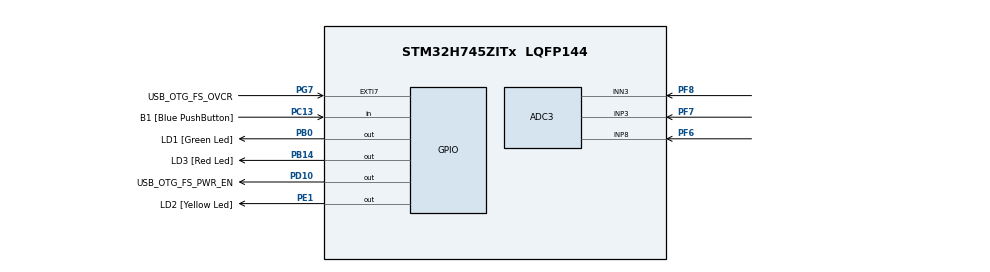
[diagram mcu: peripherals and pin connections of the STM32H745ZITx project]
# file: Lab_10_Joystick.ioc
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ADC3.Channel-0\#ChannelRegularConversion=ADC_CHANNEL_8
ADC3.Channel-1\#ChannelRegularConversion=ADC_CHANNEL_3
ADC3.DiscontinuousConvMode=ENABLE
ADC3.NbrOfConversion=2
ADC3.NbrOfConversionFlag=1
ADC3.OffsetNumber-0\#ChannelRegularConversion=ADC_OFFSET_NONE
ADC3.OffsetNumber-1\#ChannelRegularConversion=ADC_OFFSET_NONE
ADC3.OffsetSignedSaturation-0\#ChannelRegularConversion=DISABLE
ADC3.OffsetSignedSaturation-1\#ChannelRegularConversion=DISABLE
ADC3.Rank-0\#ChannelRegularConversion=1
ADC3.Rank-1\#ChannelRegularConversion=2
ADC3.SamplingTime-0\#ChannelRegularConversion=ADC_SAMPLETIME_1CYCLE_5
ADC3.SamplingTime-1\#ChannelRegularConversion=ADC_SAMPLETIME_1CYCLE_5
ADC3.SingleDiff-1\#ChannelRegularConversion=ADC_DIFFERENTIAL_ENDED
CortexM4.IPs=FATFS_M4\:I,FREERTOS_M4\:I,IWDG2\:I,RCC,WWDG2\:I,DMA,BDMA,MDMA,NVIC2\:I,USART3,ETH,DEBUG,PDM2PCM_M4\:I,PWR,RESMGR_UTILITY,SYS_M4\:I,USB_DEVICE_M4\:I,USB_HOST_M4\:I,CORTEX_M4\:I,GPIO,OPENAMP_M4\:I,VREFBUF
CortexM7.IPs=FATFS_M7\:I,FREERTOS_M7\:I,IWDG1\:I,RCC\:I,WWDG1\:I,DMA\:I,BDMA\:I,MDMA\:I,NVIC1\:I,SYS\:I,USART3\:I,USB_OTG_FS\:I,ETH\:I,CORTEX_M7\:I,DEBUG\:I,PDM2PCM_M7\:I,PWR\:I,RESMGR_UTILITY\:I,USB_DEVICE_M7\:I,USB_HOST_M7\:I,GPIO\:I,OPENAMP_M7\:I,VREFBUF\:I,ADC3\:I
Mcu.Family=STM32H7
Mcu.Name=STM32H745ZITx
Mcu.Package=LQFP144
NVIC1.PriorityGroup=NVIC_PRIORITYGROUP_4
NVIC2.PriorityGroup=NVIC_PRIORITYGROUP_4
PA1.PinAttribute=CortexM7
PA1.Signal=ETH_REF_CLK
PA11.PinAttribute=CortexM7
PA11.Signal=USB_OTG_FS_DM
PA12.PinAttribute=CortexM7
PA12.Signal=USB_OTG_FS_DP
PA2.PinAttribute=CortexM7
PA2.Signal=ETH_MDIO
PA7.PinAttribute=CortexM7
PA7.Signal=ETH_CRS_DV
PA9.PinAttribute=CortexM7
PA9.Signal=USB_OTG_FS_VBUS
PB0.GPIO_Label=LD1 [Green Led]
PB0.PinAttribute=Free
PB0.Signal=GPIO_Output
PB13.PinAttribute=CortexM7
PB13.Signal=ETH_TXD1
PB14.GPIO_Label=LD3 [Red Led]
PB14.PinAttribute=Free
PB14.Signal=GPIO_Output
PC13.GPIO_Label=B1 [Blue PushButton]
PC13.PinAttribute=Free
PC13.Signal=GPIO_Input
PC14-OSC32_IN\ (OSC32_IN).PinAttribute=CortexM7
PC14-OSC32_IN\ (OSC32_IN).Signal=RCC_OSC32_IN
PC15-OSC32_OUT\ (OSC32_OUT).PinAttribute=CortexM7
PC15-OSC32_OUT\ (OSC32_OUT).Signal=RCC_OSC32_OUT
PC4.PinAttribute=CortexM7
PC4.Signal=ETH_RXD0
PC5.PinAttribute=CortexM7
PC5.Signal=ETH_RXD1
PD10.GPIO_Label=USB_OTG_FS_PWR_EN
PD10.PinAttribute=Free
PD10.Signal=GPIO_Output
PD8.GPIO_Label=STLINK_RX
PD8.PinAttribute=CortexM7
PD8.Signal=USART3_TX
PD9.GPIO_Label=STLINK_TX
PD9.PinAttribute=CortexM7
PD9.Signal=USART3_RX
PE1.GPIO_Label=LD2 [Yellow Led]
PE1.PinAttribute=Free
PE1.Signal=GPIO_Output
PF6.Mode=IN8-Single-Ended
PF6.PinAttribute=CortexM7
PF6.Signal=ADC3_INP8
PF7.Mode=IN3-Differential
PF7.PinAttribute=CortexM7
PF7.Signal=ADC3_INP3
PF8.Mode=IN3-Differential
PF8.PinAttribute=CortexM7
PF8.Signal=ADC3_INN3
PG11.PinAttribute=CortexM7
PG11.Signal=ETH_TX_EN
PG13.PinAttribute=CortexM7
PG13.Signal=ETH_TXD0
PG7.GPIO_Label=USB_OTG_FS_OVCR
PG7.PinAttribute=Free
PG7.Signal=GPXTI7
PH0-OSC_IN\ (PH0).Mode=HSE-External-Clock-Source
PH0-OSC_IN\ (PH0).PinAttribute=CortexM7
PH0-OSC_IN\ (PH0).Signal=RCC_OSC_IN
PH1-OSC_OUT\ (PH1).PinAttribute=CortexM7
PH1-OSC_OUT\ (PH1).Signal=RCC_OSC_OUT
ProjectManager.HeapSize=M4-0x200,M7-0x200
ProjectManager.StackSize=M4-0x400,M7-0x400
ProjectManager.TargetToolchain=STM32CubeIDE
RCC.ADCCLockSelection=RCC_ADCCLKSOURCE_CLKP
RCC.ADCFreq_Value=64000000
RCC.APB1Freq_Value=100000000
RCC.APB2Freq_Value=100000000
RCC.APB3Freq_Value=100000000
RCC.APB4Freq_Value=100000000
RCC.CortexFreq_Value=400000000
RCC.D1PPRE=RCC_APB3_DIV2
RCC.D2PPRE1=RCC_APB1_DIV2
RCC.D2PPRE2=RCC_APB2_DIV2
RCC.D3PPRE=RCC_APB4_DIV2
RCC.DIVM1=4
RCC.DIVM3=22
RCC.DIVN1=400
RCC.DIVN3=169
RCC.DIVQ3=4
RCC.HCLKFreq_Value=200000000
RCC.HPRE=RCC_HCLK_DIV2
RCC.HSE_VALUE=8000000
RCC.PLL2FRACN=0
RCC.PLL3FRACN=0
RCC.PLLFRACN=0
RCC.PLLSourceVirtual=RCC_PLLSOURCE_HSE
RCC.SYSCLKFreq_VALUE=400000000
RCC.SYSCLKSource=RCC_SYSCLKSOURCE_PLLCLK
RCC.SupplySource=PWR_DIRECT_SMPS_SUPPLY
RCC.USBCLockSelection=RCC_USBCLKSOURCE_PLL3
RCC.USBFreq_Value=15363636.363636363
VP_SYS_M4_VS_Systick.Mode=SysTick
board=NUCLEO-H745ZI-Q

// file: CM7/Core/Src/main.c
/* USER CODE BEGIN Header */
/**
  ******************************************************************************
  * @file           : main.c
  * @brief          : Main program body
  ******************************************************************************
  * @attention
  *
  * Copyright (c) 2024 STMicroelectronics.
  * All rights reserved.
  *
  * This software is licensed under terms that can be found in the LICENSE file
  * in the root directory of this software component.
  * If no LICENSE file comes with this software, it is provided AS-IS.
  *
  ******************************************************************************
  */
/* USER CODE END Header */
#include <stdio.h>
#include <stdbool.h>
#include "main.h"

/* USER CODE BEGIN PD */
#define AdcHandle hadc3
#ifndef HSEM_ID_0
#define HSEM_ID_0 (0U) /* HW semaphore 0*/
#endif
/* USER CODE END PD */

ADC_HandleTypeDef hadc3;
__IO uint16_t x = 0;
__IO uint16_t y = 0;
float fADCxConvertedValue = 0;

void SystemClock_Config(void);
void PeriphCommonClock_Config(void);
static void MX_GPIO_Init(void);
static void MX_ADC3_Init(void);

/* USER CODE BEGIN 0 */
int __io_putchar(int ch)
{
  // Write character to ITM ch.0
  ITM_SendChar(ch);
  return(ch);
}

float map_value(float x, float x1, float x2, float y1, float y2){
    return y1 + ((x - x1) / (x2 - x1)) * (y2 - y1);
}

/* USER CODE END 0 */

int main(void)
{
/* USER CODE BEGIN Boot_Mode_Sequence_0 */
  int32_t timeout;
/* USER CODE END Boot_Mode_Sequence_0 */

/* USER CODE BEGIN Boot_Mode_Sequence_1 */
  /* Wait until CPU2 boots and enters in stop mode or timeout*/
  timeout = 0xFFFF;
  while((__HAL_RCC_GET_FLAG(RCC_FLAG_D2CKRDY) != RESET) && (timeout-- > 0));
  if ( timeout < 0 )
  {
  Error_Handler();
  }
/* USER CODE END Boot_Mode_Sequence_1 */
  /* MCU Configuration--------------------------------------------------------*/

  /* Reset of all peripherals, Initializes the Flash interface and the Systick. */
  HAL_Init();

  /* Configure the system clock */
  SystemClock_Config();

/* Configure the peripherals common clocks */
  PeriphCommonClock_Config();
/* USER CODE BEGIN Boot_Mode_Sequence_2 */
/* When system initialization is finished, Cortex-M7 will release Cortex-M4 by means of
HSEM notification */
/*HW semaphore Clock enable*/
__HAL_RCC_HSEM_CLK_ENABLE();
/*Take HSEM */
HAL_HSEM_FastTake(HSEM_ID_0);
/*Release HSEM in order to notify the CPU2(CM4)*/
HAL_HSEM_Release(HSEM_ID_0,0);
/* wait until CPU2 wakes up from stop mode */
timeout = 0xFFFF;
while((__HAL_RCC_GET_FLAG(RCC_FLAG_D2CKRDY) == RESET) && (timeout-- > 0));
if ( timeout < 0 )
{
Error_Handler();
}
/* USER CODE END Boot_Mode_Sequence_2 */

  /* Initialize all configured peripherals */
  MX_GPIO_Init();
  MX_ADC3_Init();

  /* Infinite loop */
  /* USER CODE BEGIN WHILE */
  bool read_x = false;

  int x_min = 37239;
  int x_max = 65535;

  int y_min = 900;
  int y_max = 65535;

  while (1)
  {

    /*##-3- Start the conversion process #######################################*/
    if (HAL_ADC_Start(&AdcHandle) != HAL_OK)
    {
      /* Start Conversation Error */
      Error_Handler();
    }

    /*##-4- Wait for the end of conversion #####################################*/
    /*  For simplicity reasons, this example is just waiting till the end of the
        conversion, but application may perform other tasks while conversion
        operation is ongoing. */
    if (HAL_ADC_PollForConversion(&AdcHandle, 10) != HAL_OK)
    {
      /* End Of Conversion flag not set on time */
      Error_Handler();
    }
    else
    {
      /* ADC conversion completed */
      /*##-5- Get the converted value of regular channel  ########################*/
    	if (read_x) {
    		x = HAL_ADC_GetValue(&AdcHandle);
    	}
    	else {
    		y = HAL_ADC_GetValue(&AdcHandle);
    	}

//      printf("%ld %f    %5d ", cnt, uhADCxConvertedValue);

      /* INPUT VOLTAGE = ADC Value * (Reference Voltage / ADC Resolution) */
//      fADCxConvertedValue = uhADCxConvertedValue * 3.3 / 65535;

    	int32_t x_p = -map_value(x, x_min, x_max, -100, 100);
    	int32_t y_p = map_value(y, y_min, y_max, -100, 100);

      printf("x = %ld; y = %ld V\r\n", x_p, y_p);

      read_x = !read_x;
    }

    HAL_Delay(50);
  }
  /* USER CODE END 3 */
}

void SystemClock_Config(void)
{
  RCC_OscInitTypeDef RCC_OscInitStruct = {0};
  RCC_ClkInitTypeDef RCC_ClkInitStruct = {0};

  /** Supply configuration update enable
  */
  HAL_PWREx_ConfigSupply(PWR_DIRECT_SMPS_SUPPLY);

  /** Configure the main internal regulator output voltage
  */
  __HAL_PWR_VOLTAGESCALING_CONFIG(PWR_REGULATOR_VOLTAGE_SCALE1);

  while(!__HAL_PWR_GET_FLAG(PWR_FLAG_VOSRDY)) {}

  /** Initializes the RCC Oscillators according to the specified parameters
  * in the RCC_OscInitTypeDef structure.
  */
  RCC_OscInitStruct.OscillatorType = RCC_OSCILLATORTYPE_HSI|RCC_OSCILLATORTYPE_HSE;
  RCC_OscInitStruct.HSEState = RCC_HSE_BYPASS;
  RCC_OscInitStruct.HSIState = RCC_HSI_DIV1;
  RCC_OscInitStruct.HSICalibrationValue = RCC_HSICALIBRATION_DEFAULT;
  RCC_OscInitStruct.PLL.PLLState = RCC_PLL_ON;
  RCC_OscInitStruct.PLL.PLLSource = RCC_PLLSOURCE_HSE;
  RCC_OscInitStruct.PLL.PLLM = 4;
  RCC_OscInitStruct.PLL.PLLN = 400;
  RCC_OscInitStruct.PLL.PLLP = 2;
  RCC_OscInitStruct.PLL.PLLQ = 2;
  RCC_OscInitStruct.PLL.PLLR = 2;
  RCC_OscInitStruct.PLL.PLLRGE = RCC_PLL1VCIRANGE_1;
  RCC_OscInitStruct.PLL.PLLVCOSEL = RCC_PLL1VCOWIDE;
  RCC_OscInitStruct.PLL.PLLFRACN = 0;
  if (HAL_RCC_OscConfig(&RCC_OscInitStruct) != HAL_OK)
  {
    Error_Handler();
  }

  /** Initializes the CPU, AHB and APB buses clocks
  */
  RCC_ClkInitStruct.ClockType = RCC_CLOCKTYPE_HCLK|RCC_CLOCKTYPE_SYSCLK
                              |RCC_CLOCKTYPE_PCLK1|RCC_CLOCKTYPE_PCLK2
                              |RCC_CLOCKTYPE_D3PCLK1|RCC_CLOCKTYPE_D1PCLK1;
  RCC_ClkInitStruct.SYSCLKSource = RCC_SYSCLKSOURCE_PLLCLK;
  RCC_ClkInitStruct.SYSCLKDivider = RCC_SYSCLK_DIV1;
  RCC_ClkInitStruct.AHBCLKDivider = RCC_HCLK_DIV2;
  RCC_ClkInitStruct.APB3CLKDivider = RCC_APB3_DIV2;
  RCC_ClkInitStruct.APB1CLKDivider = RCC_APB1_DIV2;
  RCC_ClkInitStruct.APB2CLKDivider = RCC_APB2_DIV2;
  RCC_ClkInitStruct.APB4CLKDivider = RCC_APB4_DIV2;

  if (HAL_RCC_ClockConfig(&RCC_ClkInitStruct, FLASH_LATENCY_2) != HAL_OK)
  {
    Error_Handler();
  }
}

void PeriphCommonClock_Config(void)
{
  RCC_PeriphCLKInitTypeDef PeriphClkInitStruct = {0};

  /** Initializes the peripherals clock
  */
  PeriphClkInitStruct.PeriphClockSelection = RCC_PERIPHCLK_CKPER;
  PeriphClkInitStruct.CkperClockSelection = RCC_CLKPSOURCE_HSI;
  if (HAL_RCCEx_PeriphCLKConfig(&PeriphClkInitStruct) != HAL_OK)
  {
    Error_Handler();
  }
}

static void MX_ADC3_Init(void)
{

  ADC_ChannelConfTypeDef sConfig = {0};

  /** Common config
  */
  hadc3.Instance = ADC3;
  hadc3.Init.Resolution = ADC_RESOLUTION_16B;
  hadc3.Init.ScanConvMode = ADC_SCAN_ENABLE;
  hadc3.Init.EOCSelection = ADC_EOC_SINGLE_CONV;
  hadc3.Init.LowPowerAutoWait = DISABLE;
  hadc3.Init.ContinuousConvMode = DISABLE;
  hadc3.Init.NbrOfConversion = 2;
  hadc3.Init.DiscontinuousConvMode = ENABLE;
  hadc3.Init.NbrOfDiscConversion = 1;
  hadc3.Init.ExternalTrigConv = ADC_SOFTWARE_START;
  hadc3.Init.ExternalTrigConvEdge = ADC_EXTERNALTRIGCONVEDGE_NONE;
  hadc3.Init.ConversionDataManagement = ADC_CONVERSIONDATA_DR;
  hadc3.Init.Overrun = ADC_OVR_DATA_PRESERVED;
  hadc3.Init.LeftBitShift = ADC_LEFTBITSHIFT_NONE;
  hadc3.Init.OversamplingMode = DISABLE;
  if (HAL_ADC_Init(&hadc3) != HAL_OK)
  {
    Error_Handler();
  }

  /** Configure Regular Channel
  */
  sConfig.Channel = ADC_CHANNEL_8;
  sConfig.Rank = ADC_REGULAR_RANK_1;
  sConfig.SamplingTime = ADC_SAMPLETIME_1CYCLE_5;
  sConfig.SingleDiff = ADC_SINGLE_ENDED;
  sConfig.OffsetNumber = ADC_OFFSET_NONE;
  sConfig.Offset = 0;
  sConfig.OffsetSignedSaturation = DISABLE;
  if (HAL_ADC_ConfigChannel(&hadc3, &sConfig) != HAL_OK)
  {
    Error_Handler();
  }

  /** Configure Regular Channel
  */
  sConfig.Channel = ADC_CHANNEL_3;
  sConfig.Rank = ADC_REGULAR_RANK_2;
  sConfig.SingleDiff = ADC_DIFFERENTIAL_ENDED;
  if (HAL_ADC_ConfigChannel(&hadc3, &sConfig) != HAL_OK)
  {
    Error_Handler();
  }

}

static void MX_GPIO_Init(void)
{
  GPIO_InitTypeDef GPIO_InitStruct = {0};

  /* GPIO Ports Clock Enable */
  __HAL_RCC_GPIOC_CLK_ENABLE();
  __HAL_RCC_GPIOF_CLK_ENABLE();
  __HAL_RCC_GPIOH_CLK_ENABLE();
  __HAL_RCC_GPIOA_CLK_ENABLE();
  __HAL_RCC_GPIOB_CLK_ENABLE();
  __HAL_RCC_GPIOD_CLK_ENABLE();
  __HAL_RCC_GPIOG_CLK_ENABLE();

  /*Configure GPIO pins : PA1 PA2 PA7 */
  GPIO_InitStruct.Pin = GPIO_PIN_1|GPIO_PIN_2|GPIO_PIN_7;
  GPIO_InitStruct.Mode = GPIO_MODE_AF_PP;
  GPIO_InitStruct.Pull = GPIO_NOPULL;
  GPIO_InitStruct.Speed = GPIO_SPEED_FREQ_LOW;
  GPIO_InitStruct.Alternate = GPIO_AF11_ETH;
  HAL_GPIO_Init(GPIOA, &GPIO_InitStruct);

  /*Configure GPIO pins : PC4 PC5 */
  GPIO_InitStruct.Pin = GPIO_PIN_4|GPIO_PIN_5;
  GPIO_InitStruct.Mode = GPIO_MODE_AF_PP;
  GPIO_InitStruct.Pull = GPIO_NOPULL;
  GPIO_InitStruct.Speed = GPIO_SPEED_FREQ_LOW;
  GPIO_InitStruct.Alternate = GPIO_AF11_ETH;
  HAL_GPIO_Init(GPIOC, &GPIO_InitStruct);

  /*Configure GPIO pin : PB13 */
  GPIO_InitStruct.Pin = GPIO_PIN_13;
  GPIO_InitStruct.Mode = GPIO_MODE_AF_PP;
  GPIO_InitStruct.Pull = GPIO_NOPULL;
  GPIO_InitStruct.Speed = GPIO_SPEED_FREQ_LOW;
  GPIO_InitStruct.Alternate = GPIO_AF11_ETH;
  HAL_GPIO_Init(GPIOB, &GPIO_InitStruct);

  /*Configure GPIO pins : PD8 PD9 */
  GPIO_InitStruct.Pin = GPIO_PIN_8|GPIO_PIN_9;
  GPIO_InitStruct.Mode = GPIO_MODE_AF_PP;
  GPIO_InitStruct.Pull = GPIO_NOPULL;
  GPIO_InitStruct.Speed = GPIO_SPEED_FREQ_LOW;
  GPIO_InitStruct.Alternate = GPIO_AF7_USART3;
  HAL_GPIO_Init(GPIOD, &GPIO_InitStruct);

  /*Configure GPIO pins : PA11 PA12 */
  GPIO_InitStruct.Pin = GPIO_PIN_11|GPIO_PIN_12;
  GPIO_InitStruct.Mode = GPIO_MODE_AF_PP;
  GPIO_InitStruct.Pull = GPIO_NOPULL;
  GPIO_InitStruct.Speed = GPIO_SPEED_FREQ_LOW;
  GPIO_InitStruct.Alternate = GPIO_AF10_OTG1_FS;
  HAL_GPIO_Init(GPIOA, &GPIO_InitStruct);

  /*Configure GPIO pins : PG11 PG13 */
  GPIO_InitStruct.Pin = GPIO_PIN_11|GPIO_PIN_13;
  GPIO_InitStruct.Mode = GPIO_MODE_AF_PP;
  GPIO_InitStruct.Pull = GPIO_NOPULL;
  GPIO_InitStruct.Speed = GPIO_SPEED_FREQ_LOW;
  GPIO_InitStruct.Alternate = GPIO_AF11_ETH;
  HAL_GPIO_Init(GPIOG, &GPIO_InitStruct);

}

void Error_Handler(void)
{
  __disable_irq();
  while (1)
  {
  }
}
